# STM32U5G7 register map
File version: 1.1
CPU: CM33 r0p1, little endian, MPU, FPU, 4 interrupt priority bits
Registers are 32-bit, read-write, reset 0x0 unless marked. A register's access mark holds for its fields unless they carry their own. Offsets are from the block's base; [hi:lo] are bit positions; {n}, {i} and the like mark numbered series; 'fields as' and 'values as' point back to an identical list.

## FLASH
Base 0x40022000
Same registers: SEC_FLASH 0x50022000
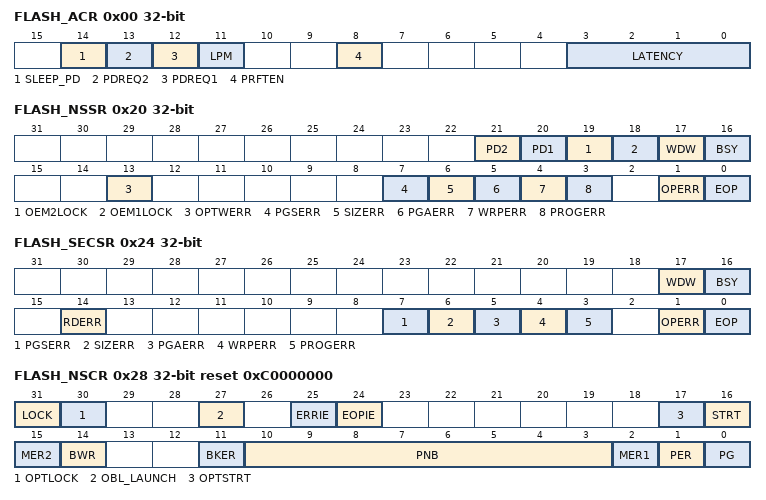
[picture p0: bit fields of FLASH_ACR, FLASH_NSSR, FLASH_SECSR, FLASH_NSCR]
0x00 FLASH_ACR — FLASH access control register
  [14] SLEEP_PD — Flash memory power-down mode during Sleep mode
    0=Flash in Idle mode during Sleep mode; 1=Flash in power-down mode during Sleep mode
  [13] PDREQ2 — Bank 2 power-down mode request
    0=No request for bank 2 to enter power-down mode; 1=Bank 2 requested to enter power-down mode
  [12] PDREQ1 — Bank 1 power-down mode request
    0=No request for bank 1 to enter power-down mode; 1=Bank 1 requested to enter power-down mode
  [11] LPM — Low-power read mode
    0=Flash not in low-power read mode; 1=Flash in low-power read mode
  [8] PRFTEN — Prefetch enable
    0=Prefetch disabled; 1=Prefetch enabled
  [3:0] LATENCY
    0=Zero wait state; 1=One wait state; 2=Two wait states; 15=Fifteen wait states
0x08 FLASH_NSKEYR wo — FLASH non-secure key register
  [31:0] NSKEY — Flash memory non-secure key
0x0C FLASH_SECKEYR wo — FLASH secure key register
  [31:0] SECKEY — Flash memory secure key
0x10 FLASH_OPTKEYR wo — FLASH option key register
  [31:0] OPTKEY — Option byte key
0x18 FLASH_PDKEY1R wo — FLASH bank 1 power-down key register
  [31:0] PDKEY1 — Bank 1 power-down key
0x1C FLASH_PDKEY2R wo — FLASH bank 2 power-down key register
  [31:0] PDKEY2 — Bank 2 power-down key
0x20 FLASH_NSSR (reset mask 0xFFF0FFFF) — FLASH non-secure status register
  [21] PD2 ro — Bank 2 in power-down mode
  [20] PD1 ro — Bank 1 in power-down mode
  [19] OEM2LOCK ro
  [18] OEM1LOCK ro
  [17] WDW ro — Non-secure wait data to write
  [16] BSY ro — Non-secure busy
  [13] OPTWERR — Option write error
  [7] PGSERR — Non-secure programming sequence error
  [6] SIZERR — Non-secure size error
  [5] PGAERR — Non-secure programming alignment error
  [4] WRPERR — Non-secure write protection error
  [3] PROGERR — Non-secure programming error
  [1] OPERR — Non-secure operation error
  [0] EOP — Non-secure end of operation
0x24 FLASH_SECSR — FLASH secure status register
  [17] WDW ro — Secure wait data to write
  [16] BSY ro — Secure busy
  [14] RDERR — Secure readout protection error
  [7] PGSERR — Secure programming sequence error
  [6] SIZERR — Secure size error
  [5] PGAERR — Secure programming alignment error
  [4] WRPERR — Secure write protection error
  [3] PROGERR — Secure programming error
  [1] OPERR — Secure operation error
  [0] EOP — Secure end of operation
0x28 FLASH_NSCR reset 0xC0000000 — FLASH non-secure control register
  [31] LOCK — Non-secure lock
  [30] OPTLOCK — Option lock
  [27] OBL_LAUNCH — Force the option byte loading
    0=Option byte loading complete; 1=Option byte loading requested
  [25] ERRIE — Non-secure error interrupt enable
    0=Non-secure OPERR error interrupt disabled; 1=Non-secure OPERR error interrupt enabled
  [24] EOPIE — Non-secure end of operation interrupt enable
    0=Non-secure EOP Interrupt disabled; 1=Non-secure EOP Interrupt enabled
  [17] OPTSTRT — Options modification start
  [16] STRT — Non-secure start
  [15] MER2 — Non-secure bank 2 mass erase
  [14] BWR — Non-secure burst write programming mode
  [11] BKER — Non-secure bank selection for page erase
    0=Bank 1 selected for non-secure page erase; 1=Bank 2 selected for non-secure page erase
  [10:3] PNB — Non-secure page number selection
    0=page 0; 1=page 1; 127=page 127 (upper page for STM32U575/585); 255=page 255 (upper page for STM32U59x/5Ax)
  [2] MER1 — Non-secure bank 1 mass erase
  [1] PER — Non-secure page erase
    0=Non-secure page erase disabled; 1=Non-secure page erase enabled
  [0] PG — Non-secure programming
    0=Non-secure Flash programming disabled; 1=Non-secure Flash programming enabled
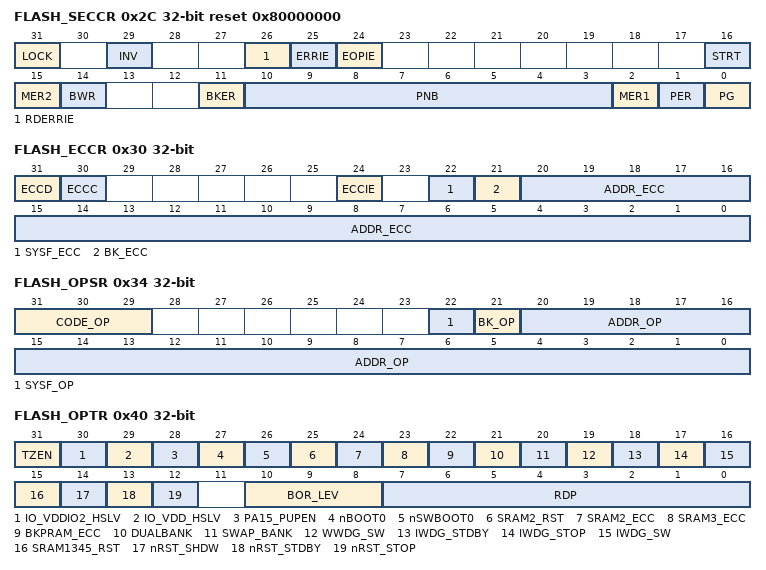
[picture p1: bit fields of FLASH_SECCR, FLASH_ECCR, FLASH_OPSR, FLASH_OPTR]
0x2C FLASH_SECCR reset 0x80000000 — FLASH secure control register
  [31] LOCK — Secure lock
  [29] INV — Flash memory security state invert
  [26] RDERRIE — Secure PCROP read error interrupt enable
    0=Secure PCROP read error interrupt disabled; 1=Secure PCROP read error interrupt enabled
  [25] ERRIE — Secure error interrupt enable
    0=Secure OPERR error interrupt disabled; 1=Secure OPERR error interrupt enabled
  [24] EOPIE — Secure End of operation interrupt enable
    0=Secure EOP Interrupt disabled; 1=Secure EOP Interrupt enabled
  [16] STRT — Secure start
  [15] MER2 — Secure bank 2 mass erase
  [14] BWR — Secure burst write programming mode
  [11] BKER — Secure bank selection for page erase
    0=Bank 1 selected for secure page erase; 1=Bank 2 selected for secure page erase
  [10:3] PNB — Secure page number selection
    values as FLASH_NSCR.PNB
  [2] MER1 — Secure bank 1 mass erase
  [1] PER — Secure page erase
    0=Secure page erase disabled; 1=Secure page erase enabled
  [0] PG — Secure programming
    0=Secure Flash programming disabled; 1=Secure Flash programming enabled
0x30 FLASH_ECCR — FLASH ECC register
  [31] ECCD — ECC detection
  [30] ECCC — ECC correction
  [24] ECCIE — ECC correction interrupt enable
    0=ECCC interrupt disabled; 1=ECCC interrupt enabled
  [22] SYSF_ECC ro — System Flash memory ECC fail
  [21] BK_ECC ro — ECC fail bank
    0=Bank 1; 1=Bank 2
  [20:0] ADDR_ECC ro — ECC fail address
0x34 FLASH_OPSR ro (reset mask 0xF000000) — FLASH operation status register
  [31:29] CODE_OP — Flash memory operation code
    0=No Flash operation interrupted by previous reset; 1=Single write operation interrupted; 2=Burst write operation interrupted; 3=Page erase operation interrupted; 4=Bank erase operation interrupted; 5=Mass erase operation interrupted; 6=Option change operation interrupted
  [22] SYSF_OP — Operation in system Flash memory interrupted
  [21] BK_OP — Interrupted operation bank
    0=Bank 1; 1=Bank 2
  [20:0] ADDR_OP — Interrupted operation address
0x40 FLASH_OPTR reset not defined — FLASH option register
  [31] TZEN — Global TrustZone security enable
    0=Global TrustZone security disabled; 1=Global TrustZone security enabled
  [30] IO_VDDIO2_HSLV — High-speed IO at low VDDIO2 voltage configuration bit
    0=High-speed IO at low VDDIO2 voltage feature disabled (VDDIO2 can exceed 2.5 V); 1=High-speed IO at low VDDIO2 voltage feature enabled (VDDIO2 remains below 2.5 V)
  [29] IO_VDD_HSLV — High-speed IO at low VDD voltage configuration bit
    0=High-speed IO at low VDD voltage feature disabled (VDD can exceed 2.5 V); 1=High-speed IO at low VDD voltage feature enabled (VDD remains below 2.5 V)
  [28] PA15_PUPEN — PA15 pull-up enable
    0=USB power delivery dead-battery enabled/TDI pull-up deactivated; 1=USB power delivery dead-battery disabled/TDI pull-up activated
  [27] nBOOT0 — nBOOT0 option bit
    0=nBOOT0 = 0; 1=nBOOT0 = 1
  [26] nSWBOOT0 — Software BOOT0
    0=BOOT0 taken from the option bit nBOOT0; 1=BOOT0 taken from PH3/BOOT0 pin
  [25] SRAM2_RST — SRAM2 erase when system reset
    0=SRAM2 erased when a system reset occurs; 1=SRAM2 not erased when a system reset occurs
  [24] SRAM2_ECC — SRAM2 ECC detection and correction enable
    0=SRAM2 ECC check enabled; 1=SRAM2 ECC check disabled
  [23] SRAM3_ECC — SRAM3 ECC detection and correction enable
    0=SRAM3 ECC check enabled; 1=SRAM3 ECC check disabled
  [22] BKPRAM_ECC — Backup RAM ECC detection and correction enable
    0=Backup RAM ECC check enabled; 1=Backup RAM ECC check disabled
  [21] DUALBANK — Dual-bank on 1-Mbyte and 512-Kbyte Flash memory devices
    0=Single bank Flash with contiguous address in bank 1; 1=Dual-bank Flash with contiguous addresses
  [20] SWAP_BANK — Swap banks
    0=Bank 1 and bank 2 addresses not swapped; 1=Bank 1 and bank 2 addresses swapped
  [19] WWDG_SW — Window watchdog selection
    0=Hardware window watchdog selected; 1=Software window watchdog selected
  [18] IWDG_STDBY — Independent watchdog counter freeze in Standby mode
    0=Independent watchdog counter frozen in Standby mode; 1=Independent watchdog counter running in Standby mode
  [17] IWDG_STOP — Independent watchdog counter freeze in Stop mode
    0=Independent watchdog counter frozen in Stop mode; 1=Independent watchdog counter running in Stop mode
  [16] IWDG_SW — Independent watchdog selection
    0=Hardware independent watchdog selected; 1=Software independent watchdog selected
  [15] SRAM1345_RST — SRAM1, SRAM3, SRAM4 and SRAM5 erase upon system reset
    0=SRAM1, SRAM3, SRAM4 and SRAM5 erased when a system reset occurs; 1=SRAM1, SRAM3, SRAM4 and SRAM5 not erased when a system reset occurs
  [14] nRST_SHDW — Reset generation in Shutdown mode
    0=Reset generated when entering the Shutdown mode; 1=No reset generated when entering the Shutdown mode
  [13] nRST_STDBY — Reset generation in Standby mode
    0=Reset generated when entering the Standby mode; 1=No reset generate when entering the Standby mode
  [12] nRST_STOP — Reset generation in Stop mode
    0=Reset generated when entering the Stop mode; 1=No reset generated when entering the Stop mode
  [10:8] BOR_LEV — BOR reset level
    0=BOR level 0 (reset level threshold around 1.7 V); 1=BOR level 1 (reset level threshold around 2.0 V); 2=BOR level 2 (reset level threshold around 2.2 V); 3=BOR level 3 (reset level threshold around 2.5 V); 4=BOR level 4 (reset level threshold around 2.8 V)
  [7:0] RDP — Readout protection level
    170=Level 0 (readout protection not active); 85=Level 0.5 (readout protection not active, only non-secure debug access is possible). Only available when TrustZone is active (TZEN=1); 204=Level 2 (chip readout protection active)
0x44 FLASH_NSBOOTADD0R reset 0xF (reset mask 0xF) — FLASH non-secure boot address 0 register
  [31:7] NSBOOTADD0 — Non-secure boot base address 0
0x48 FLASH_NSBOOTADD1R reset 0xF (reset mask 0xF) — FLASH non-secure boot address 1 register
  [31:7] NSBOOTADD1 — Non-secure boot address 1
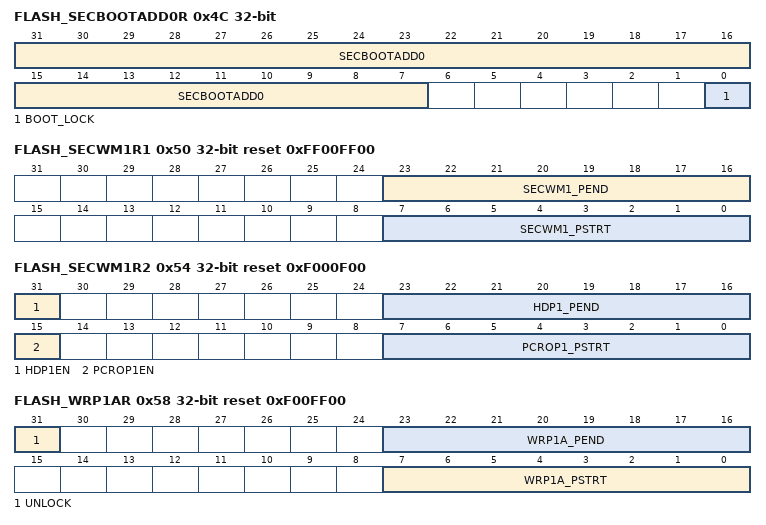
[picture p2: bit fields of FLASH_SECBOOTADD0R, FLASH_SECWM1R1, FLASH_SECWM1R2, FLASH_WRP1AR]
0x4C FLASH_SECBOOTADD0R reset not defined — FLASH secure boot address 0 register
  [31:7] SECBOOTADD0 — Secure boot base address 0
  [0] BOOT_LOCK
0x50 FLASH_SECWM1R1 reset 0xFF00FF00 (reset mask 0xFF00FF00) — FLASH secure watermark1 register 1
  [23:16] SECWM1_PEND — End page of first secure area
  [7:0] SECWM1_PSTRT — Start page of first secure area
0x54 FLASH_SECWM1R2 reset 0xF000F00 (reset mask 0xF000F00) — FLASH secure watermark1 register 2
  [31] HDP1EN — Hide protection first area enable
    0=No HDP area 1; 1=HDP first area enabled
  [23:16] HDP1_PEND — End page of first hide protection area
  [15] PCROP1EN — PCROP1 area enable
    0=PCROP1 area disabled; 1=PCROP1 area enabled
  [7:0] PCROP1_PSTRT — Start page of first PCROP area
0x58 FLASH_WRP1AR reset 0xF00FF00 (reset mask 0xF00FF00) — FLASH WRP1 area A address register
  [31] UNLOCK — Bank 1 WPR first area A unlock
    0=WRP1A start and end pages locked; 1=WRP1A start and end pages unlocked
  [23:16] WRP1A_PEND — Bank 1 WPR first area A end page
  [7:0] WRP1A_PSTRT — bank 1 WPR first area A start page
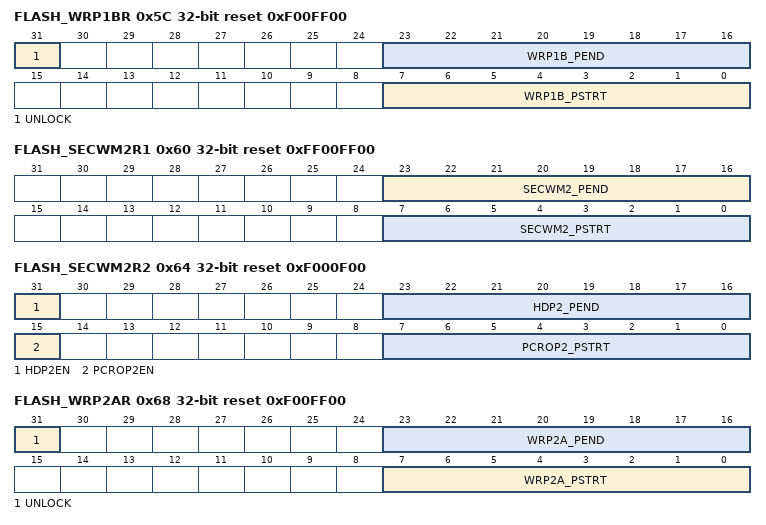
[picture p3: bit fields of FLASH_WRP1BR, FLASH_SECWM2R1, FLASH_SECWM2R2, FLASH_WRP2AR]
0x5C FLASH_WRP1BR reset 0xF00FF00 (reset mask 0xF00FF00) — FLASH WRP1 area B address register
  [31] UNLOCK — Bank 1 WPR second area B unlock
    0=WRP1B start and end pages locked; 1=WRP1B start and end pages unlocked
  [23:16] WRP1B_PEND — Bank 1 WRP second area B end page
  [7:0] WRP1B_PSTRT — Bank 1 WRP second area B start page
0x60 FLASH_SECWM2R1 reset 0xFF00FF00 (reset mask 0xFF00FF00) — FLASH secure watermark2 register 1
  [23:16] SECWM2_PEND — End page of second secure area
  [7:0] SECWM2_PSTRT — Start page of second secure area
0x64 FLASH_SECWM2R2 reset 0xF000F00 (reset mask 0xF000F00) — FLASH secure watermark2 register 2
  [31] HDP2EN — Hide protection second area enable
    0=No HDP area 2; 1=HDP second area is enabled
  [23:16] HDP2_PEND — End page of hide protection second area
  [15] PCROP2EN — PCROP2 area enable
    0=PCROP2 area is disabled; 1=PCROP2 area is enabled
  [7:0] PCROP2_PSTRT — Start page of PCROP2 area
0x68 FLASH_WRP2AR reset 0xF00FF00 (reset mask 0xF00FF00) — FLASH WPR2 area A address register
  [31] UNLOCK — Bank 2 WPR first area A unlock
    0=WRP2A start and end pages locked; 1=WRP2A start and end pages unlocked
  [23:16] WRP2A_PEND — Bank 2 WPR first area A end page
  [7:0] WRP2A_PSTRT — Bank 2 WPR first area A start page
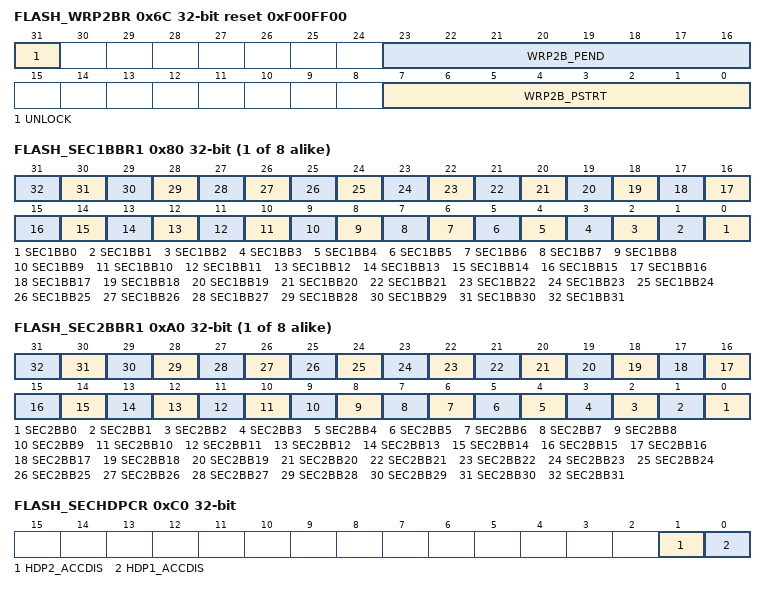
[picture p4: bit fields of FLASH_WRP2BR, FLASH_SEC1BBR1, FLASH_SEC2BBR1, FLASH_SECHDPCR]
0x6C FLASH_WRP2BR reset 0xF00FF00 (reset mask 0xF00FF00) — FLASH WPR2 area B address register
  [31] UNLOCK — Bank 2 WPR second area B unlock
    0=WRP2B start and end pages locked; 1=WRP2B start and end pages unlocked
  [23:16] WRP2B_PEND — Bank 2 WPR second area B end page
  [7:0] WRP2B_PSTRT — Bank 2 WPR second area B start page
0x70 FLASH_OEM1KEYR1 wo — FLASH OEM1 key register 1
  [31:0] OEM1KEY — OEM1 least significant bytes key
0x74 FLASH_OEM1KEYR2 wo — FLASH OEM1 key register 2
  [31:0] OEM1KEY — OEM1 most significant bytes key
0x78 FLASH_OEM2KEYR1 wo — FLASH OEM2 key register 1
  [31:0] OEM2KEY — OEM2 least significant bytes key
0x7C FLASH_OEM2KEYR2 wo — FLASH OEM2 key register 2
  [31:0] OEM2KEY — OEM2 most significant bytes key
{0x7C+4i} FLASH_SEC1BBR{i} (i=1..8) — FLASH secure block based bank 1 register {i}
  [n] SEC1BB{n} (n=0..31)
{0x9C+4i} FLASH_SEC2BBR{i} (i=1..8) — FLASH secure block based bank 2 register {i}
  [n] SEC2BB{n} (n=0..31)
0xC0 FLASH_SECHDPCR — FLASH secure HDP control register
  [1] HDP2_ACCDIS — HDP2 area access disable
    0=Access to HDP2 area granted; 1=Access to HDP2 area denied (SECWM2Ry option bytes modification bocked -refer to )
  [0] HDP1_ACCDIS — HDP1 area access disable
    0=Access to HDP1 area granted; 1=Access to HDP1 area denied (SECWM1Ry option bytes modification blocked - refer to )
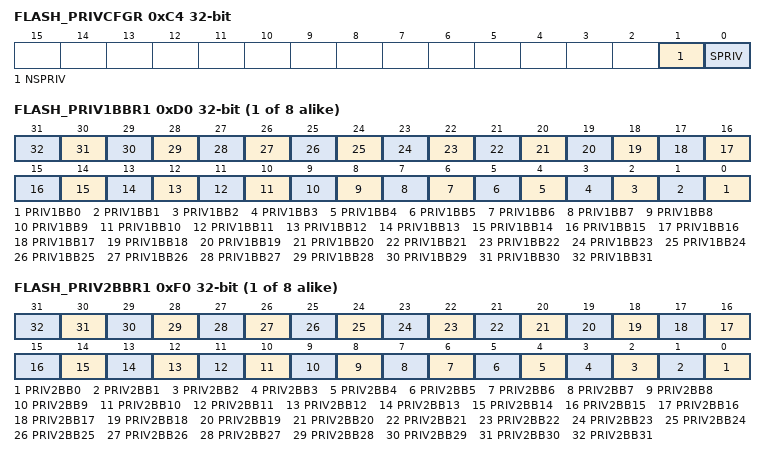
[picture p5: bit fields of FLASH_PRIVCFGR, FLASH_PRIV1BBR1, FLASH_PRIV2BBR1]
0xC4 FLASH_PRIVCFGR — FLASH privilege configuration register
  [1] NSPRIV — Privileged protection for non-secure registers
  [0] SPRIV — Privileged protection for secure registers
{0xCC+4i} FLASH_PRIV1BBR{i} (i=1..8) — FLASH privilege block based bank 1 register {i}
  [n] PRIV1BB{n} (n=0..31)
{0xEC+4i} FLASH_PRIV2BBR{i} (i=1..8) — FLASH privilege block based bank 2 register {i}
  [n] PRIV2BB{n} (n=0..31)

## Notices in the file
Copyright (c) 2024 STMicroelectronics.
SPDX-License-Identifier: Apache-2.0
Licensed under the Apache License, Version 2.0 (the "License");
you may not use this file except in compliance with the License.
You may obtain a copy of the License at
http://www.apache.org/licenses/LICENSE-2.0
Unless required by applicable law or agreed to in writing, software
distributed under the License is distributed on an "AS IS" BASIS,
WITHOUT WARRANTIES OR CONDITIONS OF ANY KIND, either express or implied.
See the License for the specific language governing permissions and
limitations under the License.
